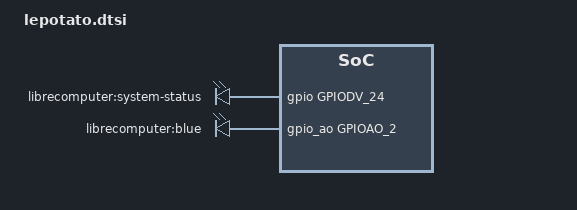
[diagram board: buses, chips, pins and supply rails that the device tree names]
/ {
	leds: gpio_leds {
		compatible = "gpio-leds";

		system {
			label = "librecomputer:system-status";
			gpios = <&gpio GPIODV_24 GPIO_ACTIVE_HIGH>;
			default-state = "off";
			panic-indicator;
		};

		blue {
			label = "librecomputer:blue";
			gpios = <&gpio_ao GPIOAO_2 GPIO_ACTIVE_HIGH>;
			default-state = "off";
		};
	};

	gpio_keypad {
		status = "disabled";
	};

	/delete-node/ partitions;
};
